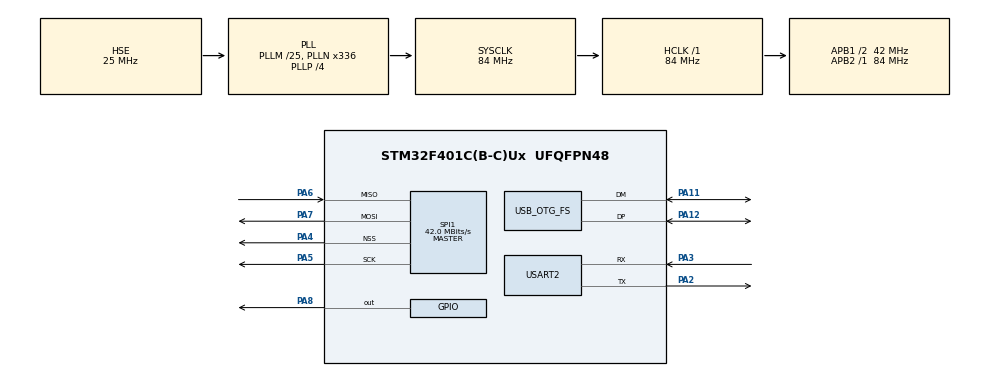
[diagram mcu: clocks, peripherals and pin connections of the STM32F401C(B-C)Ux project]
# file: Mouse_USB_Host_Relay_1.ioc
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Dma.Request0=USART2_RX
Dma.Request1=USART2_TX
Dma.Request2=SPI1_RX
Dma.Request3=SPI1_TX
Dma.SPI1_RX.2.Direction=DMA_PERIPH_TO_MEMORY
Dma.SPI1_RX.2.FIFOMode=DMA_FIFOMODE_DISABLE
Dma.SPI1_RX.2.Instance=DMA2_Stream0
Dma.SPI1_RX.2.MemDataAlignment=DMA_MDATAALIGN_BYTE
Dma.SPI1_RX.2.MemInc=DMA_MINC_ENABLE
Dma.SPI1_RX.2.Mode=DMA_NORMAL
Dma.SPI1_RX.2.PeriphDataAlignment=DMA_PDATAALIGN_BYTE
Dma.SPI1_RX.2.PeriphInc=DMA_PINC_DISABLE
Dma.SPI1_RX.2.Priority=DMA_PRIORITY_LOW
Dma.SPI1_TX.3.Direction=DMA_MEMORY_TO_PERIPH
Dma.SPI1_TX.3.FIFOMode=DMA_FIFOMODE_DISABLE
Dma.SPI1_TX.3.Instance=DMA2_Stream3
Dma.SPI1_TX.3.MemDataAlignment=DMA_MDATAALIGN_BYTE
Dma.SPI1_TX.3.MemInc=DMA_MINC_ENABLE
Dma.SPI1_TX.3.Mode=DMA_NORMAL
Dma.SPI1_TX.3.PeriphDataAlignment=DMA_PDATAALIGN_BYTE
Dma.SPI1_TX.3.PeriphInc=DMA_PINC_DISABLE
Dma.SPI1_TX.3.Priority=DMA_PRIORITY_LOW
Dma.USART2_RX.0.Direction=DMA_PERIPH_TO_MEMORY
Dma.USART2_RX.0.FIFOMode=DMA_FIFOMODE_DISABLE
Dma.USART2_RX.0.Instance=DMA1_Stream5
Dma.USART2_RX.0.MemDataAlignment=DMA_MDATAALIGN_BYTE
Dma.USART2_RX.0.MemInc=DMA_MINC_ENABLE
Dma.USART2_RX.0.Mode=DMA_NORMAL
Dma.USART2_RX.0.PeriphDataAlignment=DMA_PDATAALIGN_BYTE
Dma.USART2_RX.0.PeriphInc=DMA_PINC_DISABLE
Dma.USART2_RX.0.Priority=DMA_PRIORITY_LOW
Dma.USART2_TX.1.Direction=DMA_MEMORY_TO_PERIPH
Dma.USART2_TX.1.FIFOMode=DMA_FIFOMODE_DISABLE
Dma.USART2_TX.1.Instance=DMA1_Stream6
Dma.USART2_TX.1.MemDataAlignment=DMA_MDATAALIGN_BYTE
Dma.USART2_TX.1.MemInc=DMA_MINC_ENABLE
Dma.USART2_TX.1.Mode=DMA_NORMAL
Dma.USART2_TX.1.PeriphDataAlignment=DMA_PDATAALIGN_BYTE
Dma.USART2_TX.1.PeriphInc=DMA_PINC_DISABLE
Dma.USART2_TX.1.Priority=DMA_PRIORITY_LOW
Mcu.Family=STM32F4
Mcu.Name=STM32F401C(B-C)Ux
Mcu.Package=UFQFPN48
NVIC.DMA1_Stream5_IRQn=true\:0\:0\:false\:false\:true\:false\:true
NVIC.DMA1_Stream6_IRQn=true\:0\:0\:false\:false\:true\:false\:true
NVIC.DMA2_Stream0_IRQn=true\:0\:0\:false\:false\:true\:false\:true
NVIC.DMA2_Stream3_IRQn=true\:0\:0\:false\:false\:true\:false\:true
NVIC.OTG_FS_IRQn=true\:0\:0\:false\:false\:true\:true\:true
NVIC.PriorityGroup=NVIC_PRIORITYGROUP_4
NVIC.SPI1_IRQn=true\:0\:0\:false\:false\:true\:true\:true
NVIC.TIM1_TRG_COM_TIM11_IRQn=true\:0\:0\:false\:false\:true\:true\:true
NVIC.TIM1_UP_TIM10_IRQn=true\:0\:0\:false\:false\:true\:true\:true
NVIC.TIM3_IRQn=true\:0\:0\:false\:false\:true\:true\:true
NVIC.TIM4_IRQn=true\:0\:0\:false\:false\:true\:true\:true
NVIC.USART2_IRQn=true\:0\:0\:false\:false\:true\:true\:true
PA11.Mode=Host_Only
PA11.Signal=USB_OTG_FS_DM
PA12.Mode=Host_Only
PA12.Signal=USB_OTG_FS_DP
PA13.Mode=Serial_Wire
PA13.Signal=SYS_JTMS-SWDIO
PA14.Mode=Serial_Wire
PA14.Signal=SYS_JTCK-SWCLK
PA2.Mode=Asynchronous
PA2.Signal=USART2_TX
PA3.Mode=Asynchronous
PA3.Signal=USART2_RX
PA4.Mode=NSS_Signal_Hard_Output
PA4.Signal=SPI1_NSS
PA5.Mode=Full_Duplex_Master
PA5.Signal=SPI1_SCK
PA6.Mode=Full_Duplex_Master
PA6.Signal=SPI1_MISO
PA7.Mode=Full_Duplex_Master
PA7.Signal=SPI1_MOSI
PA8.Signal=GPIO_Output
PH0\ -\ OSC_IN.Mode=HSE-External-Oscillator
PH0\ -\ OSC_IN.Signal=RCC_OSC_IN
PH1\ -\ OSC_OUT.Mode=HSE-External-Oscillator
PH1\ -\ OSC_OUT.Signal=RCC_OSC_OUT
ProjectManager.HeapSize=0x200
ProjectManager.StackSize=0x400
ProjectManager.TargetToolchain=STM32CubeIDE
RCC.48MHZClocksFreq_Value=48000000
RCC.AHBFreq_Value=84000000
RCC.APB1CLKDivider=RCC_HCLK_DIV2
RCC.APB1Freq_Value=42000000
RCC.APB1TimFreq_Value=84000000
RCC.APB2Freq_Value=84000000
RCC.APB2TimFreq_Value=84000000
RCC.CortexFreq_Value=84000000
RCC.HCLKFreq_Value=84000000
RCC.HSE_VALUE=25000000
RCC.HSI_VALUE=16000000
RCC.LSE_VALUE=32768
RCC.PLLM=25
RCC.PLLN=336
RCC.PLLP=RCC_PLLP_DIV4
RCC.PLLQ=7
RCC.SYSCLKFreq_VALUE=84000000
RCC.SYSCLKSource=RCC_SYSCLKSOURCE_PLLCLK
RCC.VCOOutputFreq_Value=336000000
SPI1.BaudRatePrescaler=SPI_BAUDRATEPRESCALER_2
SPI1.CalculateBaudRate=42.0 MBits/s
SPI1.Direction=SPI_DIRECTION_2LINES
SPI1.Mode=SPI_MODE_MASTER
SPI1.VirtualNSS=VM_NSSHARD
SPI1.VirtualType=VM_MASTER
TIM10.Prescaler=8400
TIM11.AutoReloadPreload=TIM_AUTORELOAD_PRELOAD_ENABLE
TIM11.Period=10
TIM11.Prescaler=8400
TIM3.Prescaler=8400
TIM3.TIM_MasterOutputTrigger=TIM_TRGO_ENABLE
TIM4.Prescaler=8400
TIM4.TIM_MasterOutputTrigger=TIM_TRGO_ENABLE
USART2.VirtualMode=VM_ASYNC
USB_HOST.USBH_HandleTypeDef=hUsbHostFS
USB_HOST.VirtualModeFS=Hid
USB_OTG_FS.VirtualMode=Host_Only
USB_OTG_FS.phy_itface=HCD_PHY_EMBEDDED
VP_TIM10_VS_ClockSourceINT.Mode=Enable_Timer
VP_TIM11_VS_ClockSourceINT.Mode=Enable_Timer
VP_TIM3_VS_ClockSourceINT.Mode=Internal
VP_TIM4_VS_ClockSourceINT.Mode=Internal
VP_USB_HOST_VS_USB_HOST_HID_FS.Mode=HID_FS
board=custom

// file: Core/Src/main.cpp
/* USER CODE BEGIN Header */
/**
  ******************************************************************************
  * @file           : main.c
  * @brief          : Main program body
  ******************************************************************************
  * @attention
  *
  * <h2><center>&copy; Copyright (c) 2019 STMicroelectronics.
  * All rights reserved.</center></h2>
  *
  * This software component is licensed by ST under BSD 3-Clause license,
  * the "License"; You may not use this file except in compliance with the
  * License. You may obtain a copy of the License at:
  *                        opensource.org/licenses/BSD-3-Clause
  *
  ******************************************************************************
  */
/* USER CODE END Header */

#include <usb_host.hpp>
#include "main.h"
#include "usbh_def.h"
#include <cstdio>
#include "circular_buffer.hpp"
//#include "msgs.h"
#include "mmo_mouse_hid_driver.hpp"

SPI_HandleTypeDef hspi1;
DMA_HandleTypeDef hdma_spi1_rx;
DMA_HandleTypeDef hdma_spi1_tx;

TIM_HandleTypeDef htim3;
TIM_HandleTypeDef htim4;
TIM_HandleTypeDef htim10;
TIM_HandleTypeDef htim11;

UART_HandleTypeDef huart2;
DMA_HandleTypeDef hdma_usart2_rx;
DMA_HandleTypeDef hdma_usart2_tx;

void SystemClock_Config(void);
static void MX_GPIO_Init(void);
static void MX_DMA_Init(void);
static void MX_SPI1_Init(void);
static void MX_TIM3_Init(void);
static void MX_TIM4_Init(void);
static void MX_TIM10_Init(void);
static void MX_TIM11_Init(void);
static void MX_USART2_UART_Init(void);
void MX_USB_HOST_Process(void);

int tim11_count = 0;
int tim4_count = 0;
int tim10_count = 0;
int uart_tx_count = 0;

int log_filter_level = 3;
// 5: Silent
// 4: Error: Only ERROR Messages
// 3: INFO Mode: Info Messages
// 2: Verbose: Detailed Messages
// 1: Debug: All messages, including hex

#define USB_CDC_TX_BUF_SIZE 512

uint8_t spi_tx_count = 0;
char* tx_buf = 0;
char spi_tx_test[] = "Hello Mello  !!\r\n";

const uint16_t keep_alive_period = 50'000; //0.1milliseconds

CircularBuffer<USB_CDC_TX_BUF_SIZE> uart2_tx_buf;

void spi_tx_complete(SPI_HandleTypeDef *hspi){
	spi_tx_count ++;
	//debug_msg("SPI TX Complete:%d\r\n",spi_tx_count);
}

void MMO_Mouse_Driver_New_State_Callback(const MMO_Mouse_State_TypeDef &mmo_mouse_state)
{
  //verbose_msg("New MMO Mouse State\r\n");
  //PrintHexBuf((uint8_t*) &mmo_mouse_state, sizeof(mmo_mouse_state),VERBOSE_MSG);
  HAL_SPI_Transmit_DMA(&hspi1, (uint8_t*) &mmo_mouse_state, 9);
}

void timer4_period_elapsed(TIM_HandleTypeDef *htim){
	tim4_count ++;
}

void timer11_period_elapsed(TIM_HandleTypeDef *htim){
	tim11_count ++;
	//info_msg("Host alive msg.. %d\r\n",tim11_count);
}

void timer10_period_elapsed(TIM_HandleTypeDef *htim){
	tim10_count ++;
	uint8_t tx_count = 0;
	if ((uart2_tx_buf.length_of_ongoing_transmission() == 0) && (uart2_tx_buf.length_of_queue() > 0)){
		std::tie (tx_buf, tx_count) = uart2_tx_buf.longest_possible_send();
		HAL_UART_Transmit_DMA(&huart2,(uint8_t*) tx_buf, tx_count);
	}
}

void uart_transfer_completed(UART_HandleTypeDef *huart){
	uart2_tx_buf.send_complete();
	uart_tx_count ++;
}

extern "C" int _write(int file, char *ptr, int len);
int _write(int file, char *ptr, int len)
{
	if(log_filter_level <= file){
		uart2_tx_buf.write_to_queue(ptr, len);
		return len;
	}
	return 0;
}

//extern "C" uint8_t PrintHexBuf(uint8_t *buff, uint8_t len);
uint8_t PrintHexBuf(uint8_t *buff, uint8_t len, uint8_t level){
	if(log_filter_level <= level){
		for(uint8_t i = 0; i<len; i++){
			//debug_msg("%02X ",buff[i]);
			if ((i+1)%8 == 0){
				//debug_msg("\r\n");
			}
		}
		//debug_msg("\r\n");
		return len;
	}else{
		return 0;
	}
}

int main(void)
{

  /* MCU Configuration--------------------------------------------------------*/

  /* Reset of all peripherals, Initializes the Flash interface and the Systick. */
  HAL_Init();

  /* Configure the system clock */
  SystemClock_Config();

  /* Initialize all configured peripherals */
  MX_GPIO_Init();
  MX_DMA_Init();
  MX_SPI1_Init();
  MX_TIM3_Init();
  MX_TIM4_Init();
  MX_TIM10_Init();
  MX_TIM11_Init();
  MX_USART2_UART_Init();
  MX_USB_HOST_Init();
  /* USER CODE BEGIN 2 */

  HAL_TIM_RegisterCallback(&htim11,HAL_TIM_PERIOD_ELAPSED_CB_ID, timer11_period_elapsed);
  HAL_TIM_RegisterCallback(&htim10,HAL_TIM_PERIOD_ELAPSED_CB_ID, timer10_period_elapsed);
  HAL_TIM_RegisterCallback(&htim4, HAL_TIM_PERIOD_ELAPSED_CB_ID, timer4_period_elapsed);
  HAL_UART_RegisterCallback(&huart2, HAL_UART_TX_COMPLETE_CB_ID, uart_transfer_completed);
  HAL_SPI_RegisterCallback(&hspi1, HAL_SPI_TX_COMPLETE_CB_ID, spi_tx_complete);

  HAL_TIM_Base_Start_IT(&htim11);
  HAL_TIM_Base_Start_IT(&htim10);
 //HAL_TIM_Base_Start_IT(&htim4);

  /* USER CODE END 2 */

  /* Infinite loop */
  /* USER CODE BEGIN WHILE */
  //info_msg("Host Initialized...\r\n");

  while (1)
  {
    /* USER CODE END WHILE */
    MX_USB_HOST_Process();

  }
}

void SystemClock_Config(void)
{
  RCC_OscInitTypeDef RCC_OscInitStruct = {0};
  RCC_ClkInitTypeDef RCC_ClkInitStruct = {0};

  /** Configure the main internal regulator output voltage
  */
  __HAL_RCC_PWR_CLK_ENABLE();
  __HAL_PWR_VOLTAGESCALING_CONFIG(PWR_REGULATOR_VOLTAGE_SCALE2);
  /** Initializes the CPU, AHB and APB busses clocks
  */
  RCC_OscInitStruct.OscillatorType = RCC_OSCILLATORTYPE_HSE;
  RCC_OscInitStruct.HSEState = RCC_HSE_ON;
  RCC_OscInitStruct.PLL.PLLState = RCC_PLL_ON;
  RCC_OscInitStruct.PLL.PLLSource = RCC_PLLSOURCE_HSE;
  RCC_OscInitStruct.PLL.PLLM = 25;
  RCC_OscInitStruct.PLL.PLLN = 336;
  RCC_OscInitStruct.PLL.PLLP = RCC_PLLP_DIV4;
  RCC_OscInitStruct.PLL.PLLQ = 7;
  if (HAL_RCC_OscConfig(&RCC_OscInitStruct) != HAL_OK)
  {
    Error_Handler();
  }
  /** Initializes the CPU, AHB and APB busses clocks
  */
  RCC_ClkInitStruct.ClockType = RCC_CLOCKTYPE_HCLK|RCC_CLOCKTYPE_SYSCLK
                              |RCC_CLOCKTYPE_PCLK1|RCC_CLOCKTYPE_PCLK2;
  RCC_ClkInitStruct.SYSCLKSource = RCC_SYSCLKSOURCE_PLLCLK;
  RCC_ClkInitStruct.AHBCLKDivider = RCC_SYSCLK_DIV1;
  RCC_ClkInitStruct.APB1CLKDivider = RCC_HCLK_DIV2;
  RCC_ClkInitStruct.APB2CLKDivider = RCC_HCLK_DIV1;

  if (HAL_RCC_ClockConfig(&RCC_ClkInitStruct, FLASH_LATENCY_2) != HAL_OK)
  {
    Error_Handler();
  }
}

static void MX_SPI1_Init(void)
{

  /* SPI1 parameter configuration*/
  hspi1.Instance = SPI1;
  hspi1.Init.Mode = SPI_MODE_MASTER;
  hspi1.Init.Direction = SPI_DIRECTION_2LINES;
  hspi1.Init.DataSize = SPI_DATASIZE_8BIT;
  hspi1.Init.CLKPolarity = SPI_POLARITY_LOW;
  hspi1.Init.CLKPhase = SPI_PHASE_1EDGE;
  hspi1.Init.NSS = SPI_NSS_HARD_OUTPUT;
  hspi1.Init.BaudRatePrescaler = SPI_BAUDRATEPRESCALER_8;
  hspi1.Init.FirstBit = SPI_FIRSTBIT_MSB;
  hspi1.Init.TIMode = SPI_TIMODE_DISABLE;
  hspi1.Init.CRCCalculation = SPI_CRCCALCULATION_DISABLE;
  hspi1.Init.CRCPolynomial = 10;
  if (HAL_SPI_Init(&hspi1) != HAL_OK)
  {
    Error_Handler();
  }

}

static void MX_TIM3_Init(void)
{

  TIM_ClockConfigTypeDef sClockSourceConfig = {0};
  TIM_MasterConfigTypeDef sMasterConfig = {0};

  htim3.Instance = TIM3;
  htim3.Init.Prescaler = 8400;
  htim3.Init.CounterMode = TIM_COUNTERMODE_UP;
  htim3.Init.Period = 0;
  htim3.Init.ClockDivision = TIM_CLOCKDIVISION_DIV1;
  htim3.Init.AutoReloadPreload = TIM_AUTORELOAD_PRELOAD_DISABLE;
  if (HAL_TIM_Base_Init(&htim3) != HAL_OK)
  {
    Error_Handler();
  }
  sClockSourceConfig.ClockSource = TIM_CLOCKSOURCE_INTERNAL;
  if (HAL_TIM_ConfigClockSource(&htim3, &sClockSourceConfig) != HAL_OK)
  {
    Error_Handler();
  }
  sMasterConfig.MasterOutputTrigger = TIM_TRGO_ENABLE;
  sMasterConfig.MasterSlaveMode = TIM_MASTERSLAVEMODE_DISABLE;
  if (HAL_TIMEx_MasterConfigSynchronization(&htim3, &sMasterConfig) != HAL_OK)
  {
    Error_Handler();
  }

}

static void MX_TIM4_Init(void)
{

  TIM_ClockConfigTypeDef sClockSourceConfig = {0};
  TIM_MasterConfigTypeDef sMasterConfig = {0};

  htim4.Instance = TIM4;
  htim4.Init.Prescaler = 8400;
  htim4.Init.CounterMode = TIM_COUNTERMODE_UP;
  htim4.Init.Period = 10;
  htim4.Init.ClockDivision = TIM_CLOCKDIVISION_DIV1;
  htim4.Init.AutoReloadPreload = TIM_AUTORELOAD_PRELOAD_ENABLE;
  if (HAL_TIM_Base_Init(&htim4) != HAL_OK)
  {
    Error_Handler();
  }
  sClockSourceConfig.ClockSource = TIM_CLOCKSOURCE_INTERNAL;
  if (HAL_TIM_ConfigClockSource(&htim4, &sClockSourceConfig) != HAL_OK)
  {
    Error_Handler();
  }
  sMasterConfig.MasterOutputTrigger = TIM_TRGO_ENABLE;
  sMasterConfig.MasterSlaveMode = TIM_MASTERSLAVEMODE_DISABLE;
  if (HAL_TIMEx_MasterConfigSynchronization(&htim4, &sMasterConfig) != HAL_OK)
  {
    Error_Handler();
  }

}

static void MX_TIM10_Init(void)
{

  htim10.Instance = TIM10;
  htim10.Init.Prescaler = 8400;
  htim10.Init.CounterMode = TIM_COUNTERMODE_UP;
  htim10.Init.Period = 1;
  htim10.Init.ClockDivision = TIM_CLOCKDIVISION_DIV1;
  htim10.Init.AutoReloadPreload = TIM_AUTORELOAD_PRELOAD_ENABLE;
  if (HAL_TIM_Base_Init(&htim10) != HAL_OK)
  {
    Error_Handler();
  }

}

static void MX_TIM11_Init(void)
{

  htim11.Instance = TIM11;
  htim11.Init.Prescaler = 8400;
  htim11.Init.CounterMode = TIM_COUNTERMODE_UP;
  htim11.Init.Period = keep_alive_period;
  htim11.Init.ClockDivision = TIM_CLOCKDIVISION_DIV1;
  htim11.Init.AutoReloadPreload = TIM_AUTORELOAD_PRELOAD_ENABLE;
  if (HAL_TIM_Base_Init(&htim11) != HAL_OK)
  {
    Error_Handler();
  }

}

static void MX_USART2_UART_Init(void)
{

  huart2.Instance = USART2;
  huart2.Init.BaudRate = 1000000;
  huart2.Init.WordLength = UART_WORDLENGTH_8B;
  huart2.Init.StopBits = UART_STOPBITS_1;
  huart2.Init.Parity = UART_PARITY_NONE;
  huart2.Init.Mode = UART_MODE_TX_RX;
  huart2.Init.HwFlowCtl = UART_HWCONTROL_NONE;
  huart2.Init.OverSampling = UART_OVERSAMPLING_16;
  if (HAL_UART_Init(&huart2) != HAL_OK)
  {
    Error_Handler();
  }

}

static void MX_DMA_Init(void)
{

  /* DMA controller clock enable */
  __HAL_RCC_DMA1_CLK_ENABLE();
  __HAL_RCC_DMA2_CLK_ENABLE();

  /* DMA interrupt init */
  /* DMA1_Stream5_IRQn interrupt configuration */
  HAL_NVIC_SetPriority(DMA1_Stream5_IRQn, 0, 0);
  HAL_NVIC_EnableIRQ(DMA1_Stream5_IRQn);
  /* DMA1_Stream6_IRQn interrupt configuration */
  HAL_NVIC_SetPriority(DMA1_Stream6_IRQn, 0, 0);
  HAL_NVIC_EnableIRQ(DMA1_Stream6_IRQn);
  /* DMA2_Stream0_IRQn interrupt configuration */
  HAL_NVIC_SetPriority(DMA2_Stream0_IRQn, 0, 0);
  HAL_NVIC_EnableIRQ(DMA2_Stream0_IRQn);
  /* DMA2_Stream3_IRQn interrupt configuration */
  HAL_NVIC_SetPriority(DMA2_Stream3_IRQn, 0, 0);
  HAL_NVIC_EnableIRQ(DMA2_Stream3_IRQn);

}

static void MX_GPIO_Init(void)
{
  GPIO_InitTypeDef GPIO_InitStruct = {0};

  /* GPIO Ports Clock Enable */
  __HAL_RCC_GPIOH_CLK_ENABLE();
  __HAL_RCC_GPIOA_CLK_ENABLE();

  /*Configure GPIO pin Output Level */
  HAL_GPIO_WritePin(GPIOA, GPIO_PIN_8, GPIO_PIN_RESET);

  /*Configure GPIO pin : PA8 */
  GPIO_InitStruct.Pin = GPIO_PIN_8;
  GPIO_InitStruct.Mode = GPIO_MODE_OUTPUT_PP;
  GPIO_InitStruct.Pull = GPIO_NOPULL;
  GPIO_InitStruct.Speed = GPIO_SPEED_FREQ_LOW;
  HAL_GPIO_Init(GPIOA, &GPIO_InitStruct);

}

void Error_Handler(void)
{
}

/************************ (C) COPYRIGHT STMicroelectronics *****END OF FILE****/
